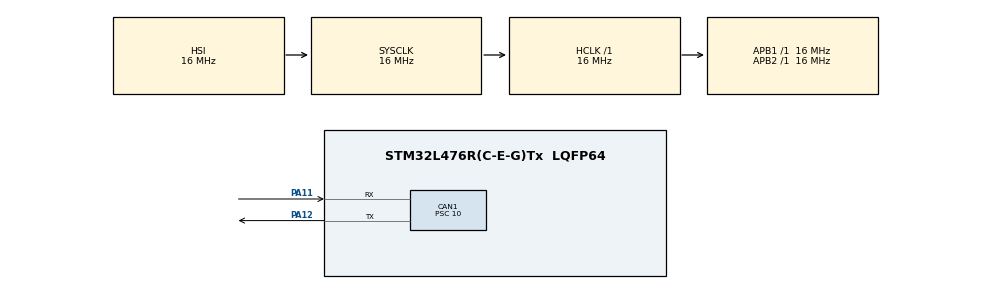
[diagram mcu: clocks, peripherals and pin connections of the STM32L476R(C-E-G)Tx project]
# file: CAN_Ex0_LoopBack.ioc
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CAN1.BS1=CAN_BS1_13TQ
CAN1.BS2=CAN_BS2_2TQ
CAN1.CalculateBaudRate=100000
CAN1.CalculateTimeBit=10000
CAN1.CalculateTimeQuantum=625.0
CAN1.Mode=CAN_MODE_LOOPBACK
CAN1.Prescaler=10
Mcu.Family=STM32L4
Mcu.Name=STM32L476R(C-E-G)Tx
Mcu.Package=LQFP64
NVIC.PriorityGroup=NVIC_PRIORITYGROUP_4
PA11.Mode=CAN_Activate
PA11.Signal=CAN1_RX
PA12.Mode=CAN_Activate
PA12.Signal=CAN1_TX
ProjectManager.HeapSize=0x200
ProjectManager.StackSize=0x400
ProjectManager.TargetToolchain=STM32CubeIDE
RCC.ADCFreq_Value=64000000
RCC.AHBFreq_Value=16000000
RCC.APB1Freq_Value=16000000
RCC.APB1TimFreq_Value=16000000
RCC.APB2Freq_Value=16000000
RCC.APB2TimFreq_Value=16000000
RCC.CortexFreq_Value=16000000
RCC.HCLKFreq_Value=16000000
RCC.HSE_VALUE=8000000
RCC.HSI_VALUE=16000000
RCC.MSI_VALUE=4000000
RCC.PLLN=10
RCC.PLLSourceVirtual=RCC_PLLSOURCE_HSI
RCC.PREFETCH_ENABLE=1
RCC.SYSCLKFreq_VALUE=16000000
RCC.SYSCLKSource=RCC_SYSCLKSOURCE_HSI
RCC.USBFreq_Value=64000000
RCC.VCOOutputFreq_Value=160000000
board=NUCLEO-L476RG

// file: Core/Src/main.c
/* USER CODE BEGIN Header */
/**
  ******************************************************************************
  * @file           : main.c
  * @brief          : Main program body
  ******************************************************************************
  * @attention
  *
  * Copyright (c) 2025 STMicroelectronics.
  * All rights reserved.
  *
  * This software is licensed under terms that can be found in the LICENSE file
  * in the root directory of this software component.
  * If no LICENSE file comes with this software, it is provided AS-IS.
  *
  ******************************************************************************
  */
/* USER CODE END Header */
#include "main.h"

/* USER CODE BEGIN Includes */
CAN_TxHeaderTypeDef   TxHeader;
CAN_RxHeaderTypeDef   RxHeader;
uint8_t               TxData[8];
uint8_t               RxData[8];
uint32_t              TxMailbox;

/* USER CODE END Includes */

CAN_HandleTypeDef hcan1;

void SystemClock_Config(void);
static void MX_GPIO_Init(void);
static void MX_CAN1_Init(void);

int main(void)
{

  /* MCU Configuration--------------------------------------------------------*/

  /* Reset of all peripherals, Initializes the Flash interface and the Systick. */
  HAL_Init();

  /* Configure the system clock */
  SystemClock_Config();

  /* Initialize all configured peripherals */
  MX_GPIO_Init();
  MX_CAN1_Init();

  /* Infinite loop */
  while (1)
  {

  }
}

void SystemClock_Config(void)
{
  RCC_OscInitTypeDef RCC_OscInitStruct = {0};
  RCC_ClkInitTypeDef RCC_ClkInitStruct = {0};

  /** Configure the main internal regulator output voltage
  */
  if (HAL_PWREx_ControlVoltageScaling(PWR_REGULATOR_VOLTAGE_SCALE1) != HAL_OK)
  {
    Error_Handler();
  }

  /** Initializes the RCC Oscillators according to the specified parameters
  * in the RCC_OscInitTypeDef structure.
  */
  RCC_OscInitStruct.OscillatorType = RCC_OSCILLATORTYPE_HSI;
  RCC_OscInitStruct.HSIState = RCC_HSI_ON;
  RCC_OscInitStruct.HSICalibrationValue = RCC_HSICALIBRATION_DEFAULT;
  RCC_OscInitStruct.PLL.PLLState = RCC_PLL_NONE;
  if (HAL_RCC_OscConfig(&RCC_OscInitStruct) != HAL_OK)
  {
    Error_Handler();
  }

  /** Initializes the CPU, AHB and APB buses clocks
  */
  RCC_ClkInitStruct.ClockType = RCC_CLOCKTYPE_HCLK|RCC_CLOCKTYPE_SYSCLK
                              |RCC_CLOCKTYPE_PCLK1|RCC_CLOCKTYPE_PCLK2;
  RCC_ClkInitStruct.SYSCLKSource = RCC_SYSCLKSOURCE_HSI;
  RCC_ClkInitStruct.AHBCLKDivider = RCC_SYSCLK_DIV1;
  RCC_ClkInitStruct.APB1CLKDivider = RCC_HCLK_DIV1;
  RCC_ClkInitStruct.APB2CLKDivider = RCC_HCLK_DIV1;

  if (HAL_RCC_ClockConfig(&RCC_ClkInitStruct, FLASH_LATENCY_0) != HAL_OK)
  {
    Error_Handler();
  }
}

static void MX_CAN1_Init(void)
{

  /*##-1- Configure the CAN peripheral #######################################*/
  hcan1.Instance = CAN1;
  hcan1.Init.Prescaler = 10;
  hcan1.Init.Mode = CAN_MODE_LOOPBACK;
  hcan1.Init.SyncJumpWidth = CAN_SJW_1TQ;
  hcan1.Init.TimeSeg1 = CAN_BS1_13TQ;
  hcan1.Init.TimeSeg2 = CAN_BS2_2TQ;
  hcan1.Init.TimeTriggeredMode = DISABLE;
  hcan1.Init.AutoBusOff = DISABLE;
  hcan1.Init.AutoWakeUp = DISABLE;
  hcan1.Init.AutoRetransmission = ENABLE; // <- deixar habilitado
  hcan1.Init.ReceiveFifoLocked = DISABLE;
  hcan1.Init.TransmitFifoPriority = DISABLE;

  if (HAL_CAN_Init(&hcan1) != HAL_OK)
  {
    Error_Handler();
  }
  /* USER CODE BEGIN CAN1_Init 2 */

	/*##-2- Configure the CAN Filter ###########################################*/

	CAN_FilterTypeDef  sFilterConfig;

	sFilterConfig.FilterBank = 0;
	sFilterConfig.FilterMode = CAN_FILTERMODE_IDMASK;
	sFilterConfig.FilterScale = CAN_FILTERSCALE_32BIT;
	sFilterConfig.FilterIdHigh = 0x0000;
	sFilterConfig.FilterIdLow = 0x0000;
	sFilterConfig.FilterMaskIdHigh = 0x0000;
	sFilterConfig.FilterMaskIdLow = 0x0000;
	sFilterConfig.FilterFIFOAssignment = CAN_RX_FIFO0;
	sFilterConfig.FilterActivation = ENABLE;
	sFilterConfig.SlaveStartFilterBank = 14;

	if(HAL_CAN_ConfigFilter(&hcan1, &sFilterConfig) != HAL_OK)
	  {
		/* Filter configuration Error */
		Error_Handler();
	  }

	/*##-3- Start the CAN peripheral ###########################################*/
	if (HAL_CAN_Start(&hcan1) != HAL_OK)
	{
	/* Start Error */
	Error_Handler();
	}

	/*##-4- Start the Transmission process #####################################*/
	TxHeader.StdId = 0x11;
	TxHeader.RTR = CAN_RTR_DATA;
	TxHeader.IDE = CAN_ID_STD;
	TxHeader.DLC = 2;
	TxHeader.TransmitGlobalTime = DISABLE;

	// Dados:
	TxData[0] = 0x03;
	TxData[1] = 0x04;

	/* Request transmission */
	if(HAL_CAN_AddTxMessage(&hcan1, &TxHeader, TxData, &TxMailbox) != HAL_OK)
	{
	/* Transmission request Error */
	Error_Handler();
	}

	/* Wait transmission complete */
	while(HAL_CAN_GetTxMailboxesFreeLevel(&hcan1) != 3) {}

	/*##-5- Start the Reception process ########################################*/
	if(HAL_CAN_GetRxFifoFillLevel(&hcan1, CAN_RX_FIFO0) != 1)
	{
	/* Reception Missing */
	Error_Handler();
	}

	if(HAL_CAN_GetRxMessage(&hcan1, CAN_RX_FIFO0, &RxHeader, RxData) != HAL_OK)
	{
	/* Reception Error */
	Error_Handler();
	}

	if((RxHeader.StdId != 0x11)                     ||
	 (RxHeader.RTR != CAN_RTR_DATA)               ||
	 (RxHeader.IDE != CAN_ID_STD)                 ||
	 (RxHeader.DLC != 2)                          ||
	 ((RxData[0]<<8 | RxData[1]) != 0xCAFE))
	{
	/* Rx message Error */
	return HAL_ERROR;
	}

  /* USER CODE END CAN1_Init 2 */

}

static void MX_GPIO_Init(void)
{

  /* GPIO Ports Clock Enable */
  __HAL_RCC_GPIOA_CLK_ENABLE();

}

void Error_Handler(void)
{
  __disable_irq();
  while (1)
  {
  }
}
